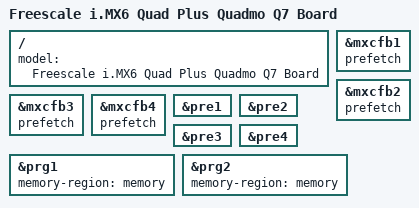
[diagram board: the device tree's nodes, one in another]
/*
 * Copyright (C) 2015 Freescale Semiconductor, Inc.
 *
 * This program is free software; you can redistribute it and/or modify
 * it under the terms of the GNU General Public License version 2 as
 * published by the Free Software Foundation.
 */

#include "imx6q-seco_quadmo747_928.dts"
#include "imx6qp.dtsi"

/ {
	model = "Freescale i.MX6 Quad Plus Quadmo Q7 Board";
};

&mxcfb1 {
	prefetch;
};

&mxcfb2 {
	prefetch;
};

&mxcfb3 {
	prefetch;
};

&mxcfb4 {
	prefetch;
};


&pre1 {
	status = "okay";
};

&pre2 {
	status = "okay";
};

&pre3 {
	status = "okay";
};

&pre4 {
	status = "okay";
};

&prg1 {
	memory-region = <&memory>;
	status = "okay";
};

&prg2 {
	memory-region = <&memory>;
	status = "okay";
};

